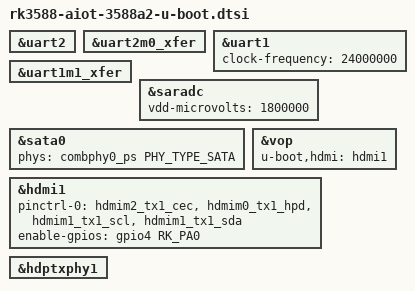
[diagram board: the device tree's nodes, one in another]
// SPDX-License-Identifier: (GPL-2.0+ OR MIT)
#include "rk3588-u-boot.dtsi"

&uart2 {
	/delete-property/ bootph-all;
};

&uart2m0_xfer {
	/delete-property/ bootph-all;
};

&uart1 {
	bootph-all;
	clock-frequency = <24000000>;
};

&uart1m1_xfer {
	bootph-all;
};

&saradc {
	vdd-microvolts = <1800000>;
};

&sata0 {
	phys = <&combphy0_ps PHY_TYPE_SATA>;
	phy-names = "sata-phy";
};

&vop {
	u-boot,hdmi = <&hdmi1>;
	status = "okay";
};

&hdmi1 {
	pinctrl-names = "default";
	pinctrl-0 = <&hdmim2_tx1_cec &hdmim0_tx1_hpd
		     &hdmim1_tx1_scl &hdmim1_tx1_sda>;
	enable-gpios = <&gpio4 RK_PA0 GPIO_ACTIVE_HIGH>;
	status = "okay";
};

&hdptxphy1 {
	status = "okay";
};
